AUTOSAR XML (schema 4-0-3)
package /AppSwComponent_Dem/SwComponentType
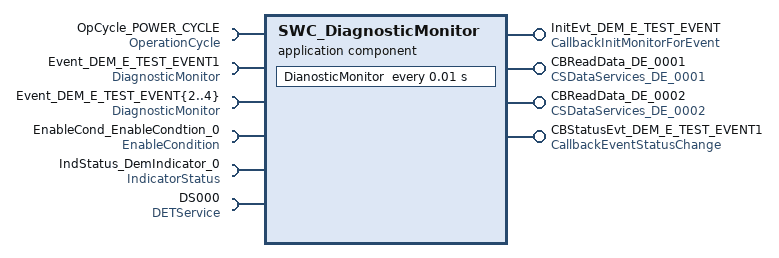
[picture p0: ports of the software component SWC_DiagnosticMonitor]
  application sw component type SWC_DiagnosticMonitor
    provide port InitEvt_DEM_E_TEST_EVENT: server-com-spec{operation=InitMonitorForEvent, queue-length=1}, provided-interface=CallbackInitMonitorForEvent
    require port OpCycle_POWER_CYCLE: client-com-spec=SetOperationCycleState, required-interface=OperationCycle
    require port Event_DEM_E_TEST_EVENT1: client-com-spec=SetEventStatus, required-interface=DiagnosticMonitor
    provide port CBReadData_DE_0001: server-com-spec{operation=ReadData, queue-length=1}, provided-interface=CSDataServices_DE_0001
    provide port CBReadData_DE_0002: server-com-spec{operation=ReadData, queue-length=1}, provided-interface=CSDataServices_DE_0002
    4 x require port:
      Event_DEM_E_TEST_EVENT{2..4}: client-com-spec=SetEventStatus, required-interface=DiagnosticMonitor
      EnableCond_EnableCondtion_0: client-com-spec=SetEnableCondition, required-interface=EnableCondition
    provide port CBStatusEvt_DEM_E_TEST_EVENT1: server-com-spec{operation=EventStatusChanged, queue-length=1}, provided-interface=CallbackEventStatusChange
    require port IndStatus_DemIndicator_0: client-com-spec=GetIndicatorStatus, required-interface=IndicatorStatus
    require port DS000: client-com-spec=ReportError, required-interface=DETService
    behavior InternalBehaviors_DiagnosticMonitor: included-data-type-set=data-type=Dem_OperationCycleStateType
      operation invoked event OIE_InitMonitorForEvent: start-on-event=InitMonitorForEvent_DEM_E_TEST, operation=InitEvt_DEM_E_TEST_EVENT.InitMonitorForEvent
      operation invoked event OIE_CBReadData_DE_0001: start-on-event=CBReadData_DE_0001, operation=CBReadData_DE_0001.ReadData
      operation invoked event OIE_CBReadData_DE_0002: start-on-event=CBReadData_DE_0002, operation=CBReadData_DE_0002.ReadData
      timing event TimingEvent_DiagnosticMonitor: start-on-event=DianosticMonitor, period=0.01
      operation invoked event OIE_CBStatusEvt_DEM_E_TEST_EVENT: start-on-event=CBStatusEvt_DEM_E_TEST_EVENT1, operation=CBStatusEvt_DEM_E_TEST_EVENT1.EventStatusChanged
      5 x runnable, all with can-be-invoked-concurrently=true:
        InitMonitorForEvent_DEM_E_TEST
        CBReadData_DE_0001
        CBReadData_DE_0002
        DianosticMonitor: symbol=DiagnosticMonitor
          8 x sync call:
            SSCP_SetOperationCycleState: operation=OpCycle_POWER_CYCLE.SetOperationCycleState
            DEM_E_TEST_EVENT{1..4}_SetEventStatus: operation=Event_DEM_E_TEST_EVENT{1..4}.SetEventStatus
            EnableCond_EnableCondition_0: operation=EnableCond_EnableCondtion_0.SetEnableCondition
            IndStatus_DemIndicator_0: operation=IndStatus_DemIndicator_0.GetIndicatorStatus
            Det_ReportError_DS000: operation=DS000.ReportError
        CBStatusEvt_DEM_E_TEST_EVENT1
  swc implementation SWC_DiagnosticMonitor_Implementation: behavior=InternalBehaviors_DiagnosticMonitor
    code-descriptors:
      code Default
